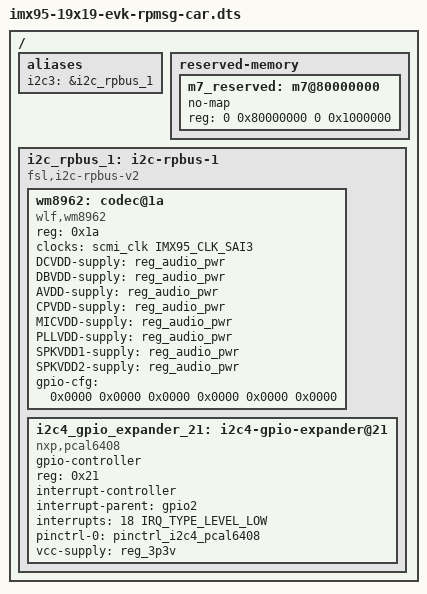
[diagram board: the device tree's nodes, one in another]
// SPDX-License-Identifier: (GPL-2.0+ OR MIT)
/*
 * Copyright 2024 NXP
 */

#include "imx95-19x19-evk.dts"

/delete-node/ &lpi2c4;

/ {
	aliases {
		i2c3 = &i2c_rpbus_1;
	};

	reserved-memory {
		m7_reserved: m7@80000000 {
			no-map;
			reg = <0 0x80000000 0 0x1000000>;
		};
	};

	i2c_rpbus_1: i2c-rpbus-1 {
		compatible = "fsl,i2c-rpbus-v2";
		#address-cells = <1>;
		#size-cells = <0>;
		status = "okay";

		wm8962: codec@1a {
			compatible = "wlf,wm8962";
			reg = <0x1a>;
			clocks = <&scmi_clk IMX95_CLK_SAI3>;
			DCVDD-supply = <&reg_audio_pwr>;
			DBVDD-supply = <&reg_audio_pwr>;
			AVDD-supply = <&reg_audio_pwr>;
			CPVDD-supply = <&reg_audio_pwr>;
			MICVDD-supply = <&reg_audio_pwr>;
			PLLVDD-supply = <&reg_audio_pwr>;
			SPKVDD1-supply = <&reg_audio_pwr>;
			SPKVDD2-supply = <&reg_audio_pwr>;
			gpio-cfg = <
				0x0000 /* 0:Default */
				0x0000 /* 1:Default */
				0x0000 /* 2:FN_DMICCLK */
				0x0000 /* 3:Default */
				0x0000 /* 4:FN_DMICCDAT */
				0x0000 /* 5:Default */
			>;
		};

		i2c4_gpio_expander_21: i2c4-gpio-expander@21 {
			compatible = "nxp,pcal6408";
			#gpio-cells = <2>;
			gpio-controller;
			reg = <0x21>;
			interrupt-controller;
			#interrupt-cells = <2>;
			interrupt-parent = <&gpio2>;
			interrupts = <18 IRQ_TYPE_LEVEL_LOW>;
			pinctrl-names = "default";
			pinctrl-0 = <&pinctrl_i2c4_pcal6408>;
			vcc-supply = <&reg_3p3v>;
			status = "okay";
		};
	};
};
